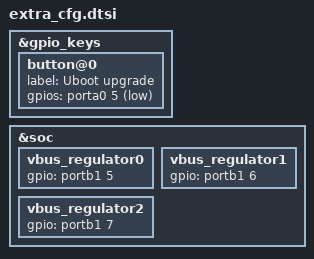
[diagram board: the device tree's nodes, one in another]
#include <dt-bindings/gpio/gpio.h>

&gpio_keys {
	button@0 {
		label = "Uboot upgrade";
		gpios = <&porta0 5 GPIO_ACTIVE_LOW>;
	};
};

&soc {
	vbus_regulator0 {
		gpio = <&portb1 5 GPIO_ACTIVE_HIGH>;
	};

	vbus_regulator1 {
		gpio = <&portb1 6 GPIO_ACTIVE_HIGH>;
	};

	vbus_regulator2 {
		gpio = <&portb1 7 GPIO_ACTIVE_HIGH>;
	};

};
